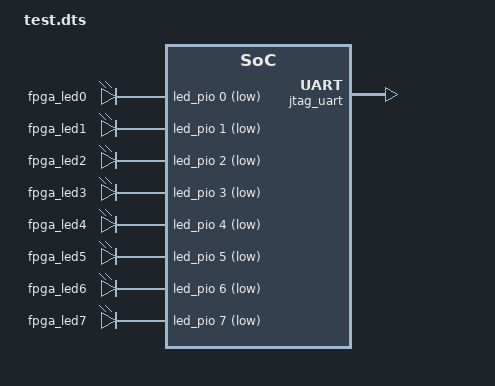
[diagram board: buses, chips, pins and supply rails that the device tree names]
/*
 * This devicetree is generated by sopc2dts version 20.1 [9b3346002ac555f36b80b1bc56dad1cb86298234] on Fri Dec 18 19:52:46 EST 2020
 * Sopc2dts is written by Walter Goossens <waltergoossens@home.nl>
 * in cooperation with the nios2 community <nios2-dev@lists.rocketboards.org>
 */

/ {

	clocks {
		#address-cells = <1>;
		#size-cells = <1>;

		clk_0: clk_0 {
			compatible = "fixed-clock";
			#clock-cells = <0>;
			clock-frequency = <50000000>;	/* 50.00 MHz */
			clock-output-names = "clk_0-clk";
		}; //end clk_0 (clk_0)

	}; //end clocks

	soc {
		ranges;
		compatible = "ALTR,avalon", "simple-bus";

		hps_0_bridges: bridge@0xc0000000 {
			compatible = "altr,bridge-20.1", "simple-bus";
			reg = <0xc0000000 0x20000000>,
				<0xff200000 0x00200000>;
			reg-names = "axi_h2f", "axi_h2f_lw";
			clocks = <&clk_0 &clk_0>;
			clock-names = "h2f_axi_clock", "h2f_lw_axi_clock";
			#address-cells = <2>;
			#size-cells = <1>;
			ranges = <0x00000000 0x00000000 0xc0000000 0x00010000>,
				<0x00000001 0x00020000 0xff220000 0x00000008>,
				<0x00000001 0x00010000 0xff210000 0x00000008>,
				<0x00000001 0x00000000 0xff200000 0x00000010>;

			jtag_uart: serial@0x100020000 {
				compatible = "altr,juart-20.1", "altr,juart-1.0";
				reg = <0x00000001 0x00020000 0x00000008>;
				interrupt-parent = <&intc>;
				interrupts = <0 42 4>;
				clocks = <&clk_0>;
			}; //end serial@0x100020000 (jtag_uart)

			sysid_qsys: sysid@0x100010000 {
				compatible = "altr,sysid-20.1", "altr,sysid-1.0";
				reg = <0x00000001 0x00010000 0x00000008>;
				clocks = <&clk_0>;
				id = <2899645186>;	/* embeddedsw.dts.params.id type NUMBER */
				timestamp = <1608338137>;	/* embeddedsw.dts.params.timestamp type NUMBER */
			}; //end sysid@0x100010000 (sysid_qsys)

			led_pio: gpio@0x100000000 {
				compatible = "altr,pio-20.1", "altr,pio-1.0";
				reg = <0x00000001 0x00000000 0x00000010>;
				clocks = <&clk_0>;
				altr,gpio-bank-width = <8>;	/* embeddedsw.dts.params.altr,gpio-bank-width type NUMBER */
				resetvalue = <255>;	/* embeddedsw.dts.params.resetvalue type NUMBER */
				#gpio-cells = <2>;
				gpio-controller;
			}; //end gpio@0x100000000 (pio_led)
		}; //end bridge@0xc0000000 (hps_0_bridges)

		soc_leds: leds {
			compatible = "gpio-leds";	/* appended from boardinfo */

			led_fpga0: fpga0 {
				label = "fpga_led0";	/* appended from boardinfo */
				gpios = <&led_pio 0 1>;	/* appended from boardinfo */
			}; //end fpga0 (led_fpga0)

			led_fpga1: fpga1 {
				label = "fpga_led1";	/* appended from boardinfo */
				gpios = <&led_pio 1 1>;	/* appended from boardinfo */
			}; //end fpga1 (led_fpga1)

			led_fpga2: fpga2 {
				label = "fpga_led2";	/* appended from boardinfo */
				gpios = <&led_pio 2 1>;	/* appended from boardinfo */
			}; //end fpga2 (led_fpga2)

			led_fpga3: fpga3 {
				label = "fpga_led3";	/* appended from boardinfo */
				gpios = <&led_pio 3 1>;	/* appended from boardinfo */
			}; //end fpga3 (led_fpga3)

			led_fpga4: fpga4 {
				label = "fpga_led4";	/* appended from boardinfo */
				gpios = <&led_pio 4 1>;	/* appended from boardinfo */
			}; //end fpga4 (led_fpga4)

			led_fpga5: fpga5 {
				label = "fpga_led5";	/* appended from boardinfo */
				gpios = <&led_pio 5 1>;	/* appended from boardinfo */
			}; //end fpga5 (led_fpga5)

			led_fpga6: fpga6 {
				label = "fpga_led6";	/* appended from boardinfo */
				gpios = <&led_pio 6 1>;	/* appended from boardinfo */
			}; //end fpga6 (led_fpga6)

			led_fpga7: fpga7 {
				label = "fpga_led7";	/* appended from boardinfo */
				gpios = <&led_pio 7 1>;	/* appended from boardinfo */
			}; //end fpga7 (led_fpga7)
		}; //end leds (soc_leds)
	}; //end sopc@0 (sopc0)
}; //end /
